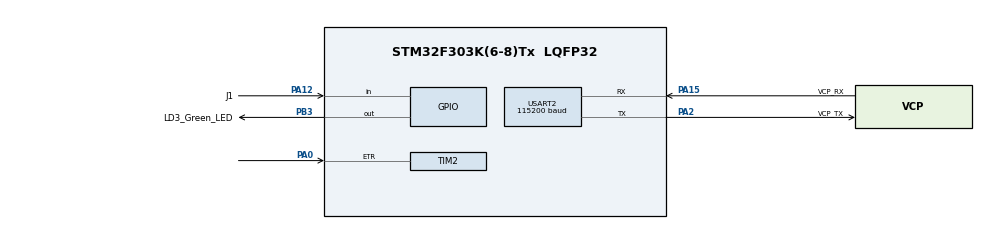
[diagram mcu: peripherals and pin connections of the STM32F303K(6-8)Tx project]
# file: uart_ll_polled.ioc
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Mcu.Family=STM32F3
Mcu.Name=STM32F303K(6-8)Tx
Mcu.Package=LQFP32
NVIC.PriorityGroup=NVIC_PRIORITYGROUP_4
NVIC.TIM2_IRQn=true\:0\:0\:false\:false\:true\:true\:true
PA0.GPIO_PuPd=GPIO_PULLDOWN
PA0.Signal=S_TIM2_CH1_ETR
PA12.GPIO_Label=J1
PA12.GPIO_PuPd=GPIO_PULLUP
PA12.Signal=GPIO_Input
PA13.GPIO_Label=SWDIO
PA13.Mode=Serial_Wire
PA13.Signal=SYS_JTMS-SWDIO
PA14.GPIO_Label=SWCLK
PA14.Mode=Serial_Wire
PA14.Signal=SYS_JTCK-SWCLK
PA15.GPIO_Label=VCP_RX
PA15.Mode=Asynchronous
PA15.Signal=USART2_RX
PA2.GPIO_Label=VCP_TX
PA2.Mode=Asynchronous
PA2.Signal=USART2_TX
PB3.GPIO_Label=LD3_Green_LED
PB3.GPIO_Speed=GPIO_SPEED_FREQ_HIGH
PB3.Signal=GPIO_Output
PF0\ /\ OSC_IN.GPIO_Label=MCO
PF0\ /\ OSC_IN.Mode=HSE-External-Clock-Source
PF0\ /\ OSC_IN.Signal=RCC_OSC_IN
ProjectManager.HeapSize=0x200
ProjectManager.StackSize=0x400
ProjectManager.TargetToolchain=STM32CubeIDE
RCC.AHBFreq_Value=64000000
RCC.APB1CLKDivider=RCC_HCLK_DIV2
RCC.APB1Freq_Value=32000000
RCC.APB1TimFreq_Value=64000000
RCC.APB2Freq_Value=64000000
RCC.APB2TimFreq_Value=64000000
RCC.CortexFreq_Value=64000000
RCC.HCLKFreq_Value=64000000
RCC.HSE_VALUE=8000000
RCC.HSI_VALUE=8000000
RCC.PLLMUL=RCC_PLL_MUL16
RCC.SYSCLKFreq_VALUE=64000000
RCC.SYSCLKSourceVirtual=RCC_SYSCLKSOURCE_PLLCLK
SH.S_TIM2_CH1_ETR.0=TIM2_ETR,ClockSourceETR_Mode2
TIM2.ClockFilter=15
TIM2.Period=5
USART2.BaudRate=115200
USART2.VirtualMode-Asynchronous=VM_ASYNC
board=NUCLEO-F303K8

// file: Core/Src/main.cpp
/* USER CODE BEGIN Header */
/**
  ******************************************************************************
  * @file           : main.c
  * @brief          : Main program body
  ******************************************************************************
  * @attention
  *
  * <h2><center>&copy; Copyright (c) 2020 STMicroelectronics.
  * All rights reserved.</center></h2>
  *
  * This software component is licensed by ST under BSD 3-Clause license,
  * the "License"; You may not use this file except in compliance with the
  * License. You may obtain a copy of the License at:
  *                        opensource.org/licenses/BSD-3-Clause
  *
  ******************************************************************************
  */
/* USER CODE END Header */
#include "main.h"

/* USER CODE BEGIN Includes */
#include "stm32_assert.h"
/* USER CODE END Includes */

void SystemClock_Config(void);
static void MX_GPIO_Init(void);
static void MX_USART2_UART_Init(void);
static void MX_TIM2_Init(void);

int main(void)
{

  /* MCU Configuration--------------------------------------------------------*/

  /* Reset of all peripherals, Initializes the Flash interface and the Systick. */

  LL_APB2_GRP1_EnableClock(LL_APB2_GRP1_PERIPH_SYSCFG);
  LL_APB1_GRP1_EnableClock(LL_APB1_GRP1_PERIPH_PWR);

  NVIC_SetPriorityGrouping(NVIC_PRIORITYGROUP_4);

  /* System interrupt init*/

  /* Configure the system clock */
  SystemClock_Config();

  /* Initialize all configured peripherals */
  MX_GPIO_Init();
  MX_USART2_UART_Init();
  MX_TIM2_Init();

  /* Infinite loop */
  /* USER CODE BEGIN WHILE */
  while (1)
  {
    while (LL_USART_IsActiveFlag_RXNE(USART2))
    {
	  const uint8_t c = LL_USART_ReceiveData8(USART2);
	  LL_USART_TransmitData8(USART2, c);
    }

    assert(!LL_USART_IsActiveFlag_ORE(USART2));
    assert(!LL_USART_IsActiveFlag_NE(USART2));
    assert(!LL_USART_IsActiveFlag_FE (USART2));
	assert(!LL_USART_IsActiveFlag_PE(USART2));
    /* USER CODE END WHILE */

  }
}

void SystemClock_Config(void)
{
  LL_FLASH_SetLatency(LL_FLASH_LATENCY_2);
  while(LL_FLASH_GetLatency()!= LL_FLASH_LATENCY_2)
  {
  }
  LL_RCC_HSI_Enable();

   /* Wait till HSI is ready */
  while(LL_RCC_HSI_IsReady() != 1)
  {

  }
  LL_RCC_HSI_SetCalibTrimming(16);
  LL_RCC_PLL_ConfigDomain_SYS(LL_RCC_PLLSOURCE_HSI_DIV_2, LL_RCC_PLL_MUL_16);
  LL_RCC_PLL_Enable();

   /* Wait till PLL is ready */
  while(LL_RCC_PLL_IsReady() != 1)
  {

  }
  LL_RCC_SetAHBPrescaler(LL_RCC_SYSCLK_DIV_1);
  LL_RCC_SetAPB1Prescaler(LL_RCC_APB1_DIV_2);
  LL_RCC_SetAPB2Prescaler(LL_RCC_APB1_DIV_1);
  LL_RCC_SetSysClkSource(LL_RCC_SYS_CLKSOURCE_PLL);

   /* Wait till System clock is ready */
  while(LL_RCC_GetSysClkSource() != LL_RCC_SYS_CLKSOURCE_STATUS_PLL)
  {

  }
  LL_Init1msTick(64000000);
  LL_SetSystemCoreClock(64000000);
}

static void MX_TIM2_Init(void)
{

  LL_TIM_InitTypeDef TIM_InitStruct = {0};

  LL_GPIO_InitTypeDef GPIO_InitStruct = {0};

  /* Peripheral clock enable */
  LL_APB1_GRP1_EnableClock(LL_APB1_GRP1_PERIPH_TIM2);

  LL_AHB1_GRP1_EnableClock(LL_AHB1_GRP1_PERIPH_GPIOA);
  /**TIM2 GPIO Configuration
  PA0   ------> TIM2_ETR
  */
  GPIO_InitStruct.Pin = LL_GPIO_PIN_0;
  GPIO_InitStruct.Mode = LL_GPIO_MODE_ALTERNATE;
  GPIO_InitStruct.Speed = LL_GPIO_SPEED_FREQ_LOW;
  GPIO_InitStruct.OutputType = LL_GPIO_OUTPUT_PUSHPULL;
  GPIO_InitStruct.Pull = LL_GPIO_PULL_DOWN;
  GPIO_InitStruct.Alternate = LL_GPIO_AF_1;
  LL_GPIO_Init(GPIOA, &GPIO_InitStruct);

  /* TIM2 interrupt Init */
  NVIC_SetPriority(TIM2_IRQn, NVIC_EncodePriority(NVIC_GetPriorityGrouping(),0, 0));
  NVIC_EnableIRQ(TIM2_IRQn);

  TIM_InitStruct.Prescaler = 0;
  TIM_InitStruct.CounterMode = LL_TIM_COUNTERMODE_UP;
  TIM_InitStruct.Autoreload = 5;
  TIM_InitStruct.ClockDivision = LL_TIM_CLOCKDIVISION_DIV1;
  LL_TIM_Init(TIM2, &TIM_InitStruct);
  LL_TIM_DisableARRPreload(TIM2);
  LL_TIM_ConfigETR(TIM2, LL_TIM_ETR_POLARITY_NONINVERTED, LL_TIM_ETR_PRESCALER_DIV1, LL_TIM_ETR_FILTER_FDIV32_N8);
  LL_TIM_SetClockSource(TIM2, LL_TIM_CLOCKSOURCE_EXT_MODE2);
  LL_TIM_SetTriggerOutput(TIM2, LL_TIM_TRGO_RESET);
  LL_TIM_DisableMasterSlaveMode(TIM2);

}

static void MX_USART2_UART_Init(void)
{

  LL_USART_InitTypeDef USART_InitStruct = {0};

  LL_GPIO_InitTypeDef GPIO_InitStruct = {0};

  /* Peripheral clock enable */
  LL_APB1_GRP1_EnableClock(LL_APB1_GRP1_PERIPH_USART2);

  LL_AHB1_GRP1_EnableClock(LL_AHB1_GRP1_PERIPH_GPIOA);
  /**USART2 GPIO Configuration
  PA2   ------> USART2_TX
  PA15   ------> USART2_RX
  */
  GPIO_InitStruct.Pin = VCP_TX_Pin|VCP_RX_Pin;
  GPIO_InitStruct.Mode = LL_GPIO_MODE_ALTERNATE;
  GPIO_InitStruct.Speed = LL_GPIO_SPEED_FREQ_HIGH;
  GPIO_InitStruct.OutputType = LL_GPIO_OUTPUT_PUSHPULL;
  GPIO_InitStruct.Pull = LL_GPIO_PULL_NO;
  GPIO_InitStruct.Alternate = LL_GPIO_AF_7;
  LL_GPIO_Init(GPIOA, &GPIO_InitStruct);

  USART_InitStruct.BaudRate = 115200;
  USART_InitStruct.DataWidth = LL_USART_DATAWIDTH_8B;
  USART_InitStruct.StopBits = LL_USART_STOPBITS_1;
  USART_InitStruct.Parity = LL_USART_PARITY_NONE;
  USART_InitStruct.TransferDirection = LL_USART_DIRECTION_TX_RX;
  USART_InitStruct.HardwareFlowControl = LL_USART_HWCONTROL_NONE;
  USART_InitStruct.OverSampling = LL_USART_OVERSAMPLING_16;
  LL_USART_Init(USART2, &USART_InitStruct);
  LL_USART_DisableIT_CTS(USART2);
  LL_USART_ConfigAsyncMode(USART2);
  LL_USART_Enable(USART2);

}

static void MX_GPIO_Init(void)
{
  LL_GPIO_InitTypeDef GPIO_InitStruct = {0};

  /* GPIO Ports Clock Enable */
  LL_AHB1_GRP1_EnableClock(LL_AHB1_GRP1_PERIPH_GPIOF);
  LL_AHB1_GRP1_EnableClock(LL_AHB1_GRP1_PERIPH_GPIOA);
  LL_AHB1_GRP1_EnableClock(LL_AHB1_GRP1_PERIPH_GPIOB);

  /**/
  LL_GPIO_ResetOutputPin(LD3_Green_LED_GPIO_Port, LD3_Green_LED_Pin);

  /**/
  GPIO_InitStruct.Pin = J1_Pin;
  GPIO_InitStruct.Mode = LL_GPIO_MODE_INPUT;
  GPIO_InitStruct.Pull = LL_GPIO_PULL_UP;
  LL_GPIO_Init(J1_GPIO_Port, &GPIO_InitStruct);

  /**/
  GPIO_InitStruct.Pin = LD3_Green_LED_Pin;
  GPIO_InitStruct.Mode = LL_GPIO_MODE_OUTPUT;
  GPIO_InitStruct.Speed = LL_GPIO_SPEED_FREQ_HIGH;
  GPIO_InitStruct.OutputType = LL_GPIO_OUTPUT_PUSHPULL;
  GPIO_InitStruct.Pull = LL_GPIO_PULL_NO;
  LL_GPIO_Init(LD3_Green_LED_GPIO_Port, &GPIO_InitStruct);

}

void Error_Handler(void)
{
}

/************************ (C) COPYRIGHT STMicroelectronics *****END OF FILE****/
